# SPC1169 register map
File version: 2022071043481212
CPU: cm4 r1p0, little endian, no MPU, FPU, 4 interrupt priority bits
Registers are 32-bit, read-write, reset 0x0 unless marked. A register's access mark holds for its fields unless they carry their own. Offsets are from the block's base; [hi:lo] are bit positions; {n}, {i} and the like mark numbered series; 'fields as' and 'values as' point back to an identical list.

## EPWR
Base 0x40000400
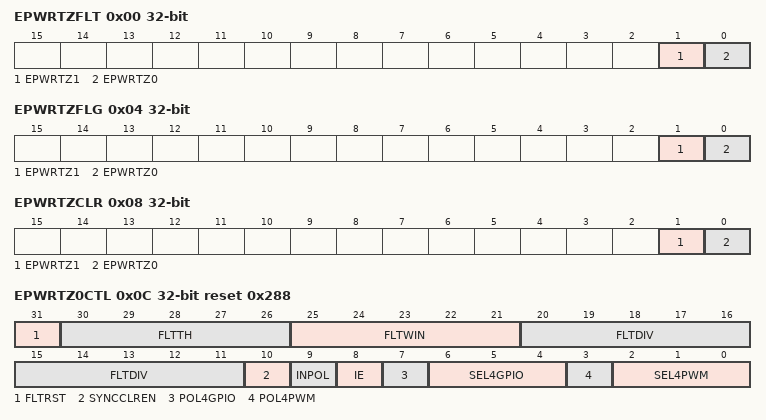
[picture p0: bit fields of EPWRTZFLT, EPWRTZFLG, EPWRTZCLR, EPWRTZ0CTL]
0x00 EPWRTZFLT ro — ePower Module Filtered Trip-Zone Event Register
  [1] EPWRTZ1 — Filtered EPWRTZ1 event without latch
    0=NOT_OCCUR (EPWRTZ1 event does not happen); 1=OCCUR (EPWRTZ1 event happened)
  [0] EPWRTZ0 — Filtered EPWRTZ0 event without latch
    0=NOT_OCCUR (EPWRTZ0 event does not happen); 1=OCCUR (EPWRTZ0 event happened)
0x04 EPWRTZFLG ro — ePower Module Latched Trip-Zone Flag Register
  [1] EPWRTZ1 — Latched EPWRTZ1 event flag after filtering
    values as EPWRTZFLT.EPWRTZ1
  [0] EPWRTZ0 — Latched EPWRTZ0 event flag after filtering
    values as EPWRTZFLT.EPWRTZ0
0x08 EPWRTZCLR — ePower Module Latched Trip-Zone Flag Clear Register
  [1] EPWRTZ1 — Latched EPWRTZ1 flag clear
    0=NO_EFFECT (Write a 0 has no effect. Always readback 0); 1=CLEAR (Write a 1 clears EPWRTZSTS[EPWRTZ1]. This bit is self-cleared.)
  [0] EPWRTZ0 — Latched EPWRTZ0 flag clear
    0=NO_EFFECT (Write a 0 has no effect. Always readback 0); 1=CLEAR (Write a 1 clears EPWRTZSTS[EPWRTZ0]. This bit is self-cleared.)
0x0C EPWRTZ0CTL reset 0x288 — ePower Module Trip-Zone Event 0 Control Register
  [31] FLTRST — Reset all registers in the filter with the input
    0=NO_EFFECT (Write 0 has no effect. Always read back 0.); 1=RESET (Write 1 will fill all registers in the filter with the input)
  [30:26] FLTTH — Filter's threhold is (FLTTH+1) 1's/0's for output to toggle
  [25:21] FLTWIN — Filter's window size is (FLTWIN+1) samples
  [20:11] FLTDIV — Filter's clock dividing ratio is (FLTDIV+1)
  [10] SYNCCLREN — Enable latched EPWRTZ0 status clear by PWMSYNC
    0=DISABLE (PWMSYNC does not affect the latched EPWRTZ0 status); 1=ENABLE (PWMSYNC will clear the latched EPWRTZ0 status)
  [9] INPOL — Trip-zone input polarity
    0=ACTIVE_LOW (Trip-zone event happens when input is low); 1=ACTIVE_HIGH (Trip-zone event happens when input is high)
  [8] IE — Trip-zone event input enable
    0=DISABLE (Disable trip-zone input); 1=ENABLE (Enable trip-zone input)
  [7] POL4GPIO — Trip-zone output polarity for GPIO
    0=ACTIVE_LOW (Output 0 upon EPWRTZ0 event); 1=ACTIVE_HIGH (Output 1 upon EPWRTZ0 event)
  [6:4] SEL4GPIO — Trip-zone output select for GPIO
    0=ORIGINAL (Original output); 1=SYNC (Synchronous output with PWM clock); 2=FILTRED (Digital filter output); 3=LATCHED (Latched digital filter output); 4=ORIGINAL_OR_LATCHED (Original output or Latched digital filter output); 5=SYNC_OR_LATCHED (Synchronous output with PWM clock or Latched digital filter output); 6=FILTERED_OR_LATCHED (Digital filter output or the latched one); 7=ORIGINAL_OR_SYNC_OR_LATCHED (Original output or Synchronous output with PWM clock or Latched digital filter output)
  [3] POL4PWM — Trip-zone output polarity for PWM
    values as POL4GPIO
  [2:0] SEL4PWM — Trip-zone output select for PWM
    values as SEL4GPIO
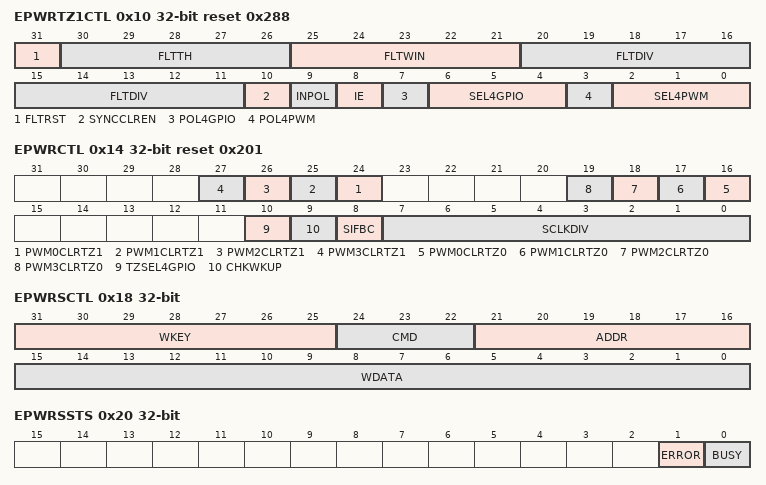
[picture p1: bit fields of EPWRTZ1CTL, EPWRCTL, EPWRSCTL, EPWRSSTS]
0x10 EPWRTZ1CTL reset 0x288 — ePower Module Trip-Zone Event 1 Control Register
  [31] FLTRST — Reset all registers in the filter with the input
    values as EPWRTZ0CTL.FLTRST
  [30:26] FLTTH — Filter's threhold is (FLTTH+1) 1's/0's for output to toggle
  [25:21] FLTWIN — Filter's window size is (FLTWIN+1) samples
  [20:11] FLTDIV — Filter's clock dividing ratio is (FLTDIV+1)
  [10] SYNCCLREN — Enable latched EPWRTZ1 status clear by PWMSYNC
    0=DISABLE (PWMSYNC does not affect the latched EPWRTZ1 status); 1=ENABLE (PWMSYNC will clear the latched EPWRTZ1 status)
  [9] INPOL — Trip-zone input polarity
    values as EPWRTZ0CTL.INPOL
  [8] IE — Trip-zone event input enable
    values as EPWRTZ0CTL.IE
  [7] POL4GPIO — Trip-zone output polarity for GPIO
    0=ACTIVE_LOW (Output 0 upon EPWRTZ1 event); 1=ACTIVE_HIGH (Output 1 upon EPWRTZ1 event)
  [6:4] SEL4GPIO — Trip-zone output select for GPIO
    values as EPWRTZ0CTL.SEL4GPIO
  [3] POL4PWM — Trip-zone output polarity for PWM
    values as POL4GPIO
  [2:0] SEL4PWM — Trip-zone output select for PWM
    values as EPWRTZ0CTL.SEL4GPIO
0x14 EPWRCTL reset 0x201 — ePower Module Control Register
  [n+24] PWM{n}CLRTZ1 (n=0..3) — Enable SYNC from PWM{n} to clear the latched EPWRTZ1 status
    0=DISABLE; 1=ENABLE
  [n+16] PWM{n}CLRTZ0 (n=0..3) — Enable SYNC from PWM{n} to clear the latched EPWRTZ0 status
    0=DISABLE; 1=ENABLE
  [10] TZSEL4GPIO — Select which TZ signal is to output to GPIO
    0=EPWRTZ0; 1=EPWRTZ1
  [9] CHKWKUP — Check wakeup condition when issue stop or sleep command
    0=NO (Do not check the wakeup condition and always issue sleep or stop command per software request); 1=YES (Check wakeup condition and do not issue sleep or stop command if wakeup condition is already met)
  [8] SIFBC — Serial interface backward compatible mode
    0=NORMAL (6-bit address & 16-bit data); 1=COMPATIBLE (5-bit address & 8-bit data)
  [7:0] SCLKDIV — Set the serial interface clock dividing ratio from HCLK to (SCLKDIV+1). The minimum value is 1. Write 0 will be ignored.
0x18 EPWRSCTL — ePower Module Serial Interface Control Register
  [31:25] WKEY — Write key for this register. Write 0x7F to this field results in: 1. Update CMD, ADDR, WDATA fields of the register. 2. Starts a new command execution. 3. Sets EPWRSTS register to 0x1. This filed is automatcally cleared to 0x0.
  [24:22] CMD — Serial interface command. For command to write register shadow value, the register address and the register value to write should be also specified. For command to read register active value, the register address should be also specified.
    0=GET_ID (Get the ePower chip ID. The returned 16-bit ID is stored in EPWRSRDAT register.); 1=WRITE_SHADOW (Write register shadow value.); 2=WRITE_ACTIVE (Write register active value from the shadow value. This command needs to be right after a succseful WR_SHADOW command. If it fails, user only needs to re-issue the WR_ACTIVE command.); 3=READ_ACTIVE (Read register active value.); 4=RESET_REG (Software reset registers.); 5=FEED_WDT (Feed the watchdog); 6=STOP (Put the whole system into stop mode); 7=SLEEP (Put the whole system into sleep mode)
  [21:16] ADDR — Register address to be read or write via the serial interface
  [15:0] WDATA — Data to write to ePower module for register with specified address.
0x1C EPWRSRDAT ro — ePower Module Serial Interface Read Data Register
  [15:0] RDATA — ePower chip ID by GET_ID command or register value readback by RD_ACTIVE command
0x20 EPWRSSTS ro — ePower Module Serial Interface Status Register
  [1] ERROR — ePower serial interface error status for the latest communication
    0=CORRECT (The latest commnucation is done without error); 1=ERROR (The latest commnucation is done with error)
  [0] BUSY — ePower serial interface bus busy status
    0=IDLE (Serial interface is idle); 1=BUSY (Serial interface is busy on communication)
0x24 EPWRREGKEY reset 0x1ACCE551 — ePower Module Register Write-Allow Key Register
  [31:0] KEY — Write 0x1ACCE551 to unlock protected registers
